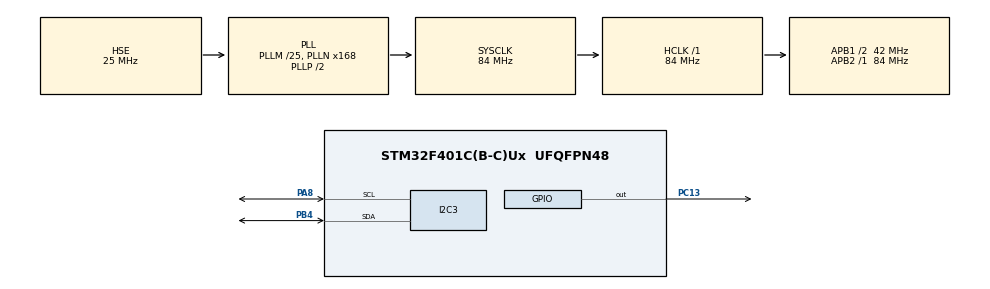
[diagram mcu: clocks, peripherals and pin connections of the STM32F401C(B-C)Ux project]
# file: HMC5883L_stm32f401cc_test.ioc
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I2C3.I2C_Mode=I2C_Fast
Mcu.Family=STM32F4
Mcu.Name=STM32F401C(B-C)Ux
Mcu.Package=UFQFPN48
NVIC.PriorityGroup=NVIC_PRIORITYGROUP_4
PA13.Mode=Serial_Wire
PA13.Signal=SYS_JTMS-SWDIO
PA14.Mode=Serial_Wire
PA14.Signal=SYS_JTCK-SWCLK
PA8.Mode=I2C
PA8.Signal=I2C3_SCL
PB4.Mode=I2C
PB4.Signal=I2C3_SDA
PC13-ANTI_TAMP.Signal=GPIO_Output
PH0\ -\ OSC_IN.Mode=HSE-External-Oscillator
PH0\ -\ OSC_IN.Signal=RCC_OSC_IN
PH1\ -\ OSC_OUT.Mode=HSE-External-Oscillator
PH1\ -\ OSC_OUT.Signal=RCC_OSC_OUT
ProjectManager.HeapSize=0x200
ProjectManager.StackSize=0x400
ProjectManager.TargetToolchain=STM32CubeIDE
RCC.48MHZClocksFreq_Value=42000000
RCC.AHBFreq_Value=84000000
RCC.APB1CLKDivider=RCC_HCLK_DIV2
RCC.APB1Freq_Value=42000000
RCC.APB1TimFreq_Value=84000000
RCC.APB2Freq_Value=84000000
RCC.APB2TimFreq_Value=84000000
RCC.CortexFreq_Value=84000000
RCC.HCLKFreq_Value=84000000
RCC.HSE_VALUE=25000000
RCC.HSI_VALUE=16000000
RCC.LSE_VALUE=32768
RCC.PLLM=25
RCC.PLLN=168
RCC.PLLSourceVirtual=RCC_PLLSOURCE_HSE
RCC.SYSCLKFreq_VALUE=84000000
RCC.SYSCLKSource=RCC_SYSCLKSOURCE_PLLCLK
RCC.VCOOutputFreq_Value=168000000
board=custom

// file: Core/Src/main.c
/* USER CODE BEGIN Header */
/**
  ******************************************************************************
  * @file           : main.c
  * @brief          : Main program body
  ******************************************************************************
  * @attention
  *
  * Copyright (c) 2024 STMicroelectronics.
  * All rights reserved.
  *
  * This software is licensed under terms that can be found in the LICENSE file
  * in the root directory of this software component.
  * If no LICENSE file comes with this software, it is provided AS-IS.
  *
  ******************************************************************************
  */
/* USER CODE END Header */
#include "main.h"

/* USER CODE BEGIN Includes */
#include"QMC5883.h"
/* USER CODE END Includes */

I2C_HandleTypeDef hi2c3;

/* USER CODE BEGIN PV */
QMC_t pusula_sensor;
float Compas_Value;
/* USER CODE END PV */

void SystemClock_Config(void);
static void MX_GPIO_Init(void);
static void MX_I2C3_Init(void);

int main(void)
{

  /* MCU Configuration--------------------------------------------------------*/

  /* Reset of all peripherals, Initializes the Flash interface and the Systick. */
  HAL_Init();

  /* Configure the system clock */
  SystemClock_Config();

  /* Initialize all configured peripherals */
  MX_GPIO_Init();
  MX_I2C3_Init();
  /* USER CODE BEGIN 2 */
  QMC_init(&pusula_sensor, &hi2c3, 200);
  /* USER CODE END 2 */

  /* Infinite loop */
  /* USER CODE BEGIN WHILE */
  while (1)
  {
		if(QMC_read(&pusula_sensor)==0)
		{
			Compas_Value=pusula_sensor.Xaxis;
		}
		HAL_Delay(50);
    /* USER CODE END WHILE */

  }
}

void SystemClock_Config(void)
{
  RCC_OscInitTypeDef RCC_OscInitStruct = {0};
  RCC_ClkInitTypeDef RCC_ClkInitStruct = {0};

  /** Configure the main internal regulator output voltage
  */
  __HAL_RCC_PWR_CLK_ENABLE();
  __HAL_PWR_VOLTAGESCALING_CONFIG(PWR_REGULATOR_VOLTAGE_SCALE2);

  /** Initializes the RCC Oscillators according to the specified parameters
  * in the RCC_OscInitTypeDef structure.
  */
  RCC_OscInitStruct.OscillatorType = RCC_OSCILLATORTYPE_HSE;
  RCC_OscInitStruct.HSEState = RCC_HSE_ON;
  RCC_OscInitStruct.PLL.PLLState = RCC_PLL_ON;
  RCC_OscInitStruct.PLL.PLLSource = RCC_PLLSOURCE_HSE;
  RCC_OscInitStruct.PLL.PLLM = 25;
  RCC_OscInitStruct.PLL.PLLN = 168;
  RCC_OscInitStruct.PLL.PLLP = RCC_PLLP_DIV2;
  RCC_OscInitStruct.PLL.PLLQ = 4;
  if (HAL_RCC_OscConfig(&RCC_OscInitStruct) != HAL_OK)
  {
    Error_Handler();
  }

  /** Initializes the CPU, AHB and APB buses clocks
  */
  RCC_ClkInitStruct.ClockType = RCC_CLOCKTYPE_HCLK|RCC_CLOCKTYPE_SYSCLK
                              |RCC_CLOCKTYPE_PCLK1|RCC_CLOCKTYPE_PCLK2;
  RCC_ClkInitStruct.SYSCLKSource = RCC_SYSCLKSOURCE_PLLCLK;
  RCC_ClkInitStruct.AHBCLKDivider = RCC_SYSCLK_DIV1;
  RCC_ClkInitStruct.APB1CLKDivider = RCC_HCLK_DIV2;
  RCC_ClkInitStruct.APB2CLKDivider = RCC_HCLK_DIV1;

  if (HAL_RCC_ClockConfig(&RCC_ClkInitStruct, FLASH_LATENCY_2) != HAL_OK)
  {
    Error_Handler();
  }
}

static void MX_I2C3_Init(void)
{

  hi2c3.Instance = I2C3;
  hi2c3.Init.ClockSpeed = 400000;
  hi2c3.Init.DutyCycle = I2C_DUTYCYCLE_2;
  hi2c3.Init.OwnAddress1 = 0;
  hi2c3.Init.AddressingMode = I2C_ADDRESSINGMODE_7BIT;
  hi2c3.Init.DualAddressMode = I2C_DUALADDRESS_DISABLE;
  hi2c3.Init.OwnAddress2 = 0;
  hi2c3.Init.GeneralCallMode = I2C_GENERALCALL_DISABLE;
  hi2c3.Init.NoStretchMode = I2C_NOSTRETCH_DISABLE;
  if (HAL_I2C_Init(&hi2c3) != HAL_OK)
  {
    Error_Handler();
  }

}

static void MX_GPIO_Init(void)
{
  GPIO_InitTypeDef GPIO_InitStruct = {0};

  /* GPIO Ports Clock Enable */
  __HAL_RCC_GPIOC_CLK_ENABLE();
  __HAL_RCC_GPIOH_CLK_ENABLE();
  __HAL_RCC_GPIOA_CLK_ENABLE();
  __HAL_RCC_GPIOB_CLK_ENABLE();

  /*Configure GPIO pin Output Level */
  HAL_GPIO_WritePin(GPIOC, GPIO_PIN_13, GPIO_PIN_RESET);

  /*Configure GPIO pin : PC13 */
  GPIO_InitStruct.Pin = GPIO_PIN_13;
  GPIO_InitStruct.Mode = GPIO_MODE_OUTPUT_PP;
  GPIO_InitStruct.Pull = GPIO_NOPULL;
  GPIO_InitStruct.Speed = GPIO_SPEED_FREQ_LOW;
  HAL_GPIO_Init(GPIOC, &GPIO_InitStruct);

}

void Error_Handler(void)
{
  __disable_irq();
  while (1)
  {
  }
}
